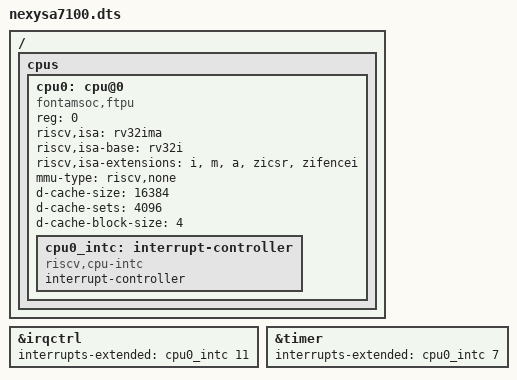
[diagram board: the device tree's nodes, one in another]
// SPDX-License-Identifier: GPL-2.0-only
// 20261120 (c) William Fonkou Tambe

// rv32-nexysa7100 with one hart, the default of nexysa7100.sv.

/dts-v1/;

#include "nexysa7100.dtsi"

/ {
	cpus {
		cpu0: cpu@0 {
			device_type = "cpu";
			reg = <0>;
			compatible = "fontamsoc,ftpu", "riscv";
			riscv,isa = "rv32ima";
			riscv,isa-base = "rv32i";
			riscv,isa-extensions = "i", "m", "a", "zicsr", "zifencei";
			mmu-type = "riscv,none";
			d-cache-size = <16384>;
			d-cache-sets = <4096>;
			d-cache-block-size = <4>;

			cpu0_intc: interrupt-controller {
				#interrupt-cells = <1>;
				interrupt-controller;
				compatible = "riscv,cpu-intc";
			};
		};
	};
};

&irqctrl {
	interrupts-extended = <&cpu0_intc 11>;
};

&timer {
	interrupts-extended = <&cpu0_intc 7>;
};
